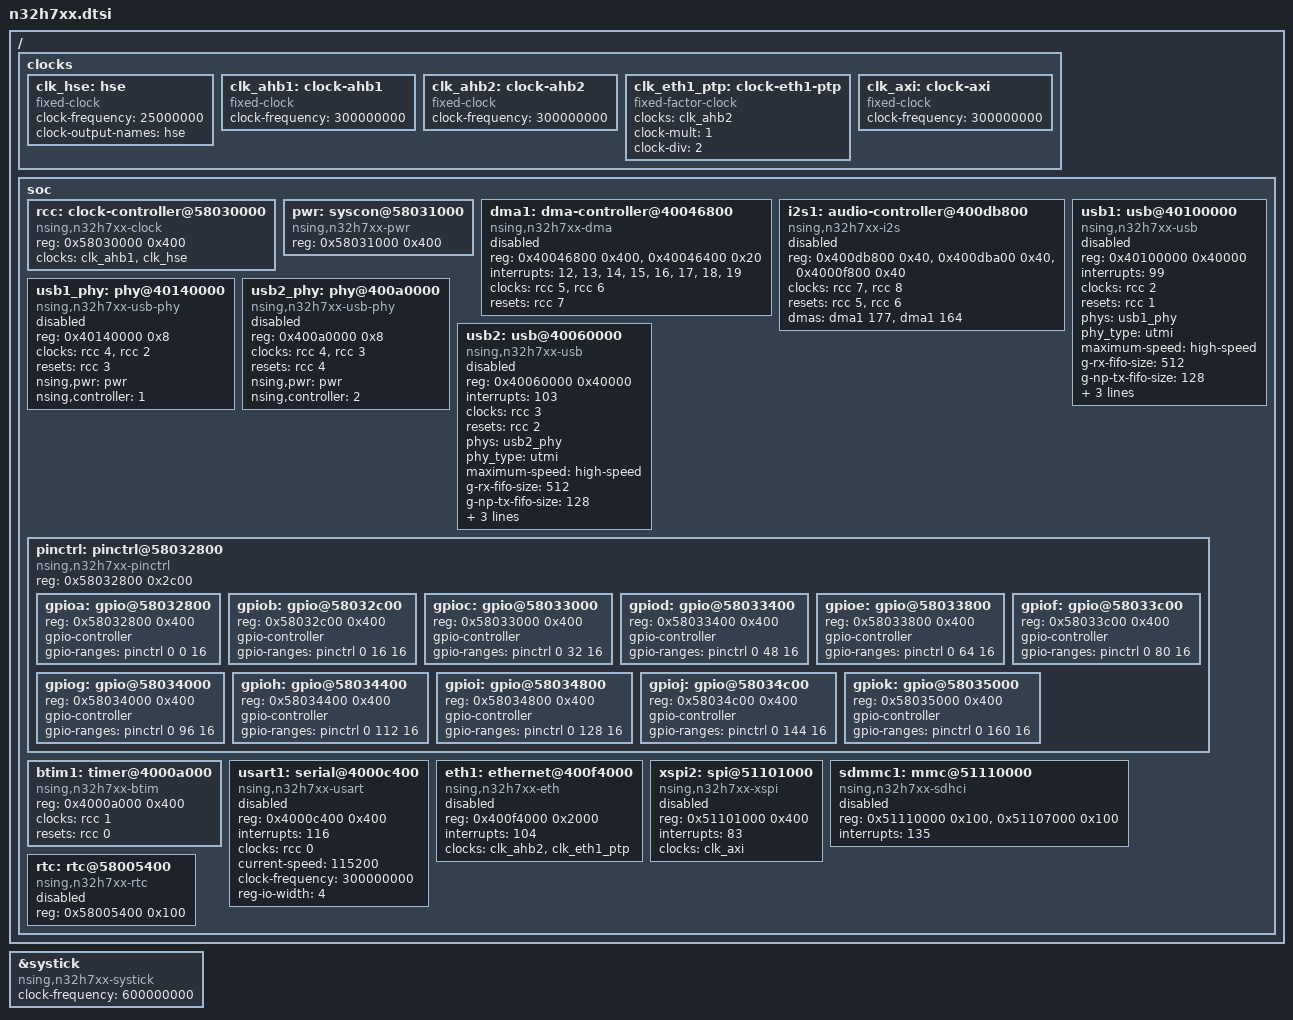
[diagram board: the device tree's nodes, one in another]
// SPDX-License-Identifier: GPL-2.0-only

#include "../armv7-m.dtsi"

/ {
	#address-cells = <1>;
	#size-cells = <1>;

	clocks {
		clk_hse: hse {
			compatible = "fixed-clock";
			#clock-cells = <0>;
			clock-frequency = <25000000>;
			clock-output-names = "hse";
		};
		clk_ahb1: clock-ahb1 {
			compatible = "fixed-clock";
			#clock-cells = <0>;
			clock-frequency = <300000000>;
		};

		/*
		 * AHB2 runs at 300 MHz on the N32H787 and is the CSR clock
		 * (the "hclk" the MAC uses for MDIO and its register block).
		 */
		clk_ahb2: clock-ahb2 {
			compatible = "fixed-clock";
			#clock-cells = <0>;
			clock-frequency = <300000000>;
		};

		/* ETH1 PTP uses the sysbus clock divided by two. */
		clk_eth1_ptp: clock-eth1-ptp {
			compatible = "fixed-factor-clock";
			clocks = <&clk_ahb2>;
			#clock-cells = <0>;
			clock-mult = <1>;
			clock-div = <2>;
		};

		/*
		 * The XSPI SSI input is the AXI bus clock, which the bootloader
		 * leaves at PLL1A/2 = 300 MHz.
		 */
		clk_axi: clock-axi {
			compatible = "fixed-clock";
			#clock-cells = <0>;
			clock-frequency = <300000000>;
		};
	};

	soc {
		rcc: clock-controller@58030000 {
			compatible = "nsing,n32h7xx-clock";
			reg = <0x58030000 0x400>;
			#clock-cells = <1>;
			#reset-cells = <1>;
			clocks = <&clk_ahb1>, <&clk_hse>;
		};

		pwr: syscon@58031000 {
			compatible = "nsing,n32h7xx-pwr", "syscon";
			reg = <0x58031000 0x400>;
		};

		dma1: dma-controller@40046800 {
			compatible = "nsing,n32h7xx-dma";
			reg = <0x40046800 0x400>, <0x40046400 0x20>;
			reg-names = "dma", "mux";
			interrupts = <12>, <13>, <14>, <15>, <16>, <17>, <18>, <19>;
			clocks = <&rcc 5>, <&rcc 6>;
			clock-names = "dma", "mux";
			resets = <&rcc 7>;
			#dma-cells = <1>;
			status = "disabled";
		};

		i2s1: audio-controller@400db800 {
			compatible = "nsing,n32h7xx-i2s";
			/*
			 * "rx" is the main block, whose data pin SD carries the
			 * codec's ADC output; "ext" is I2S1_EXT, whose SD_EXT
			 * pin carries the codec's DAC input.  The two share CK
			 * and WS and can be active together.
			 */
			reg = <0x400db800 0x40>, <0x400dba00 0x40>,
			      <0x4000f800 0x40>;
			reg-names = "rx", "ext", "mclk";
			clocks = <&rcc 7>, <&rcc 8>;
			clock-names = "rx", "mclk";
			resets = <&rcc 5>, <&rcc 6>;
			reset-names = "rx", "mclk";
			/* DMAMUX request IDs: I2S1 RX 0xB2-1, I2S1 TX 0xA5-1. */
			dmas = <&dma1 177>, <&dma1 164>;
			dma-names = "rx", "tx";
			#sound-dai-cells = <0>;
			status = "disabled";
		};

		usb1_phy: phy@40140000 {
			compatible = "nsing,n32h7xx-usb-phy";
			reg = <0x40140000 0x8>;
			#phy-cells = <0>;
			clocks = <&rcc 4>, <&rcc 2>;
			clock-names = "ref", "bus";
			resets = <&rcc 3>;
			reset-names = "por";
			nsing,pwr = <&pwr>;
			nsing,controller = <1>;
			status = "disabled";
		};

		usb2_phy: phy@400a0000 {
			compatible = "nsing,n32h7xx-usb-phy";
			reg = <0x400a0000 0x8>;
			#phy-cells = <0>;
			clocks = <&rcc 4>, <&rcc 3>;
			clock-names = "ref", "bus";
			resets = <&rcc 4>;
			reset-names = "por";
			nsing,pwr = <&pwr>;
			nsing,controller = <2>;
			status = "disabled";
		};

		usb1: usb@40100000 {
			compatible = "nsing,n32h7xx-usb", "snps,dwc2";
			reg = <0x40100000 0x40000>;
			interrupts = <99>;
			clocks = <&rcc 2>;
			clock-names = "otg";
			resets = <&rcc 1>;
			reset-names = "dwc2";
			phys = <&usb1_phy>;
			phy-names = "usb2-phy";
			phy_type = "utmi";
			maximum-speed = "high-speed";
			g-rx-fifo-size = <512>;
			g-np-tx-fifo-size = <128>;
			g-tx-fifo-size = <128 128 16 16 16 16 16 16>;
			hnp-disable;
			srp-disable;
			status = "disabled";
		};

		usb2: usb@40060000 {
			compatible = "nsing,n32h7xx-usb", "snps,dwc2";
			reg = <0x40060000 0x40000>;
			interrupts = <103>;
			clocks = <&rcc 3>;
			clock-names = "otg";
			resets = <&rcc 2>;
			reset-names = "dwc2";
			phys = <&usb2_phy>;
			phy-names = "usb2-phy";
			phy_type = "utmi";
			maximum-speed = "high-speed";
			g-rx-fifo-size = <512>;
			g-np-tx-fifo-size = <128>;
			g-tx-fifo-size = <128 128 16 16 16 16 16 16>;
			hnp-disable;
			srp-disable;
			status = "disabled";
		};

		/*
		 * The pin controller and the GPIO ports are one piece of
		 * hardware: every pin has a single register block that selects
		 * its mode and alternate function and holds its GPIO data
		 * register.  One driver registers both, and each port is a
		 * child node with its own GPIO bank.  Pin groups are described
		 * by the board under this node.
		 */
		pinctrl: pinctrl@58032800 {
			compatible = "nsing,n32h7xx-pinctrl";
			reg = <0x58032800 0x2c00>;
			#address-cells = <1>;
			#size-cells = <1>;

			gpioa: gpio@58032800 {
				reg = <0x58032800 0x400>;
				gpio-controller;
				#gpio-cells = <2>;
				gpio-ranges = <&pinctrl 0 0 16>;
			};

			gpiob: gpio@58032c00 {
				reg = <0x58032c00 0x400>;
				gpio-controller;
				#gpio-cells = <2>;
				gpio-ranges = <&pinctrl 0 16 16>;
			};

			gpioc: gpio@58033000 {
				reg = <0x58033000 0x400>;
				gpio-controller;
				#gpio-cells = <2>;
				gpio-ranges = <&pinctrl 0 32 16>;
			};

			gpiod: gpio@58033400 {
				reg = <0x58033400 0x400>;
				gpio-controller;
				#gpio-cells = <2>;
				gpio-ranges = <&pinctrl 0 48 16>;
			};

			gpioe: gpio@58033800 {
				reg = <0x58033800 0x400>;
				gpio-controller;
				#gpio-cells = <2>;
				gpio-ranges = <&pinctrl 0 64 16>;
			};

			gpiof: gpio@58033c00 {
				reg = <0x58033c00 0x400>;
				gpio-controller;
				#gpio-cells = <2>;
				gpio-ranges = <&pinctrl 0 80 16>;
			};

			gpiog: gpio@58034000 {
				reg = <0x58034000 0x400>;
				gpio-controller;
				#gpio-cells = <2>;
				gpio-ranges = <&pinctrl 0 96 16>;
			};

			gpioh: gpio@58034400 {
				reg = <0x58034400 0x400>;
				gpio-controller;
				#gpio-cells = <2>;
				gpio-ranges = <&pinctrl 0 112 16>;
			};

			gpioi: gpio@58034800 {
				reg = <0x58034800 0x400>;
				gpio-controller;
				#gpio-cells = <2>;
				gpio-ranges = <&pinctrl 0 128 16>;
			};

			gpioj: gpio@58034c00 {
				reg = <0x58034c00 0x400>;
				gpio-controller;
				#gpio-cells = <2>;
				gpio-ranges = <&pinctrl 0 144 16>;
			};

			gpiok: gpio@58035000 {
				reg = <0x58035000 0x400>;
				gpio-controller;
				#gpio-cells = <2>;
				gpio-ranges = <&pinctrl 0 160 16>;
			};
		};

		btim1: timer@4000a000 {
			compatible = "nsing,n32h7xx-btim";
			reg = <0x4000a000 0x400>;
			clocks = <&rcc 1>;
			resets = <&rcc 0>;
		};

		usart1: serial@4000c400 {
			compatible = "nsing,n32h7xx-usart";
			reg = <0x4000c400 0x400>;
			interrupts = <116>;
			clocks = <&rcc 0>;
			clock-names = "usart";
			current-speed = <115200>;
			clock-frequency = <300000000>;
			reg-io-width = <4>;
			status = "disabled";
		};

		/*
		 * ETH1 is the on-chip 10/100 Ethernet MAC.  Its MAC, MTL and
		 * DMA blocks are programmed by drivers/net/ethernet/nsing; the
		 * mach-nsing code owns the clock gates, reset, ETH1 PHY
		 * interface select and pin muxing.
		 */
		eth1: ethernet@400f4000 {
			compatible = "nsing,n32h7xx-eth";
			reg = <0x400f4000 0x2000>;
			interrupts = <104>;
			clocks = <&clk_ahb2>, <&clk_eth1_ptp>;
			clock-names = "csr", "ptp_ref";
			status = "disabled";
		};

		/*
		 * XSPI2 drives the on-board serial NOR flash.  The controller
		 * is only ever used through the spi-mem interface, so the node
		 * carries a single flash child rather than a set of chip
		 * selects.
		 */
		xspi2: spi@51101000 {
			compatible = "nsing,n32h7xx-xspi";
			reg = <0x51101000 0x400>;
			interrupts = <83>;
			clocks = <&clk_axi>;
			#address-cells = <1>;
			#size-cells = <0>;
			status = "disabled";
		};

		/*
		 * SDMMC1 is a standard SDHCI host with an NSING wrapper in
		 * front of it.  The wrapper holds the NSING-specific block
		 * length, clock and tuning capability registers.
		 */
		sdmmc1: mmc@51110000 {
			compatible = "nsing,n32h7xx-sdhci";
			reg = <0x51110000 0x100>,
			      <0x51107000 0x100>;
			reg-names = "host", "wrapper";
			interrupts = <135>;
			status = "disabled";
		};

		/*
		 * The RTC is the backup-domain calendar counter clocked from
		 * the on-board 32.768 kHz LSE crystal.  Both the oscillator and
		 * the RTC clock select are RCC/PWR bits rather than a
		 * discoverable clock, so mach-nsing brings them up from this
		 * node's probe and there is nothing to put in "clocks" yet.
		 */
		rtc: rtc@58005400 {
			compatible = "nsing,n32h7xx-rtc";
			/* APB5PERIPH_BASE + 0x5400, not the AHB5 window. */
			reg = <0x58005400 0x100>;
			status = "disabled";
		};
	};
};

&systick {
	compatible = "nsing,n32h7xx-systick";
	clock-frequency = <600000000>;
	status = "okay";
};
